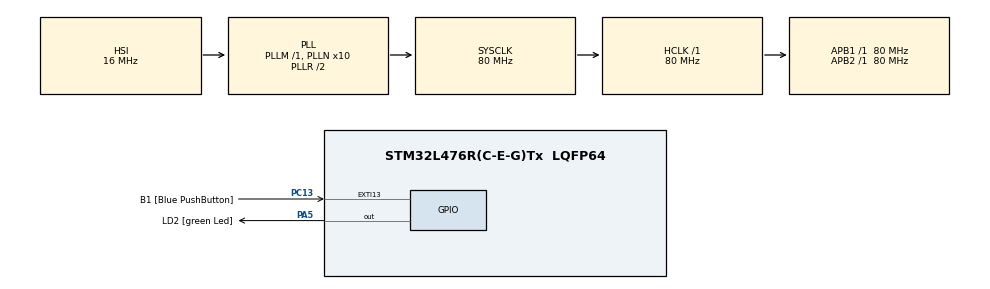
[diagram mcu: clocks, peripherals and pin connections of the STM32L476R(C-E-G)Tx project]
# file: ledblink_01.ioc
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Mcu.Family=STM32L4
Mcu.Name=STM32L476R(C-E-G)Tx
Mcu.Package=LQFP64
NVIC.PriorityGroup=NVIC_PRIORITYGROUP_4
NVIC.TIM3_IRQn=true\:0\:0\:false\:false\:true\:true
PA5.GPIO_Label=LD2 [green Led]
PA5.GPIO_ModeDefaultOutputPP=GPIO_MODE_OUTPUT_PP
PA5.GPIO_PuPd=GPIO_NOPULL
PA5.GPIO_Speed=GPIO_SPEED_FREQ_LOW
PA5.Signal=GPIO_Output
PC13.GPIO_Label=B1 [Blue PushButton]
PC13.GPIO_ModeDefaultEXTI=GPIO_MODE_IT_FALLING
PC13.GPIO_PuPd=GPIO_NOPULL
PC13.Signal=GPXTI13
PC14-OSC32_IN\ (PC14).Mode=LSE-External-Oscillator
PC14-OSC32_IN\ (PC14).Signal=RCC_OSC32_IN
PC15-OSC32_OUT\ (PC15).Mode=LSE-External-Oscillator
PC15-OSC32_OUT\ (PC15).Signal=RCC_OSC32_OUT
PH0-OSC_IN\ (PH0).Signal=RCC_OSC_IN
PH1-OSC_OUT\ (PH1).Signal=RCC_OSC_OUT
ProjectManager.HeapSize=0x200
ProjectManager.StackSize=0x400
ProjectManager.TargetToolchain=MDK-ARM V5
RCC.ADCFreq_Value=64000000
RCC.AHBFreq_Value=80000000
RCC.APB1Freq_Value=80000000
RCC.APB1TimFreq_Value=80000000
RCC.APB2Freq_Value=80000000
RCC.APB2TimFreq_Value=80000000
RCC.CortexFreq_Value=80000000
RCC.HCLKFreq_Value=80000000
RCC.HSE_VALUE=8000000
RCC.HSI_VALUE=16000000
RCC.MSI_VALUE=4000000
RCC.PLLN=10
RCC.PLLSourceVirtual=RCC_PLLSOURCE_HSI
RCC.PREFETCH_ENABLE=1
RCC.SYSCLKFreq_VALUE=80000000
RCC.SYSCLKSource=RCC_SYSCLKSOURCE_PLLCLK
RCC.USBFreq_Value=64000000
RCC.VCOOutputFreq_Value=160000000
TIM3.Prescaler=7999
VP_TIM3_VS_ClockSourceINT.Mode=Internal
board=NUCLEO-L476RG

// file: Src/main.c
/**
  ******************************************************************************
  * @file           : main.c
  * @brief          : Main program body
  ******************************************************************************
  ** This notice applies to any and all portions of this file
  * that are not between comment pairs USER CODE BEGIN and
  * USER CODE END. Other portions of this file, whether
  * inserted by the user or by software development tools
  * are owned by their respective copyright owners.
  *
  * COPYRIGHT(c) 2019 STMicroelectronics
  *
  * Redistribution and use in source and binary forms, with or without modification,
  * are permitted provided that the following conditions are met:
  *   1. Redistributions of source code must retain the above copyright notice,
  *      this list of conditions and the following disclaimer.
  *   2. Redistributions in binary form must reproduce the above copyright notice,
  *      this list of conditions and the following disclaimer in the documentation
  *      and/or other materials provided with the distribution.
  *   3. Neither the name of STMicroelectronics nor the names of its contributors
  *      may be used to endorse or promote products derived from this software
  *      without specific prior written permission.
  *
  * THIS SOFTWARE IS PROVIDED BY THE COPYRIGHT HOLDERS AND CONTRIBUTORS "AS IS"
  * AND ANY EXPRESS OR IMPLIED WARRANTIES, INCLUDING, BUT NOT LIMITED TO, THE
  * IMPLIED WARRANTIES OF MERCHANTABILITY AND FITNESS FOR A PARTICULAR PURPOSE ARE
  * DISCLAIMED. IN NO EVENT SHALL THE COPYRIGHT HOLDER OR CONTRIBUTORS BE LIABLE
  * FOR ANY DIRECT, INDIRECT, INCIDENTAL, SPECIAL, EXEMPLARY, OR CONSEQUENTIAL
  * DAMAGES (INCLUDING, BUT NOT LIMITED TO, PROCUREMENT OF SUBSTITUTE GOODS OR
  * SERVICES; LOSS OF USE, DATA, OR PROFITS; OR BUSINESS INTERRUPTION) HOWEVER
  * CAUSED AND ON ANY THEORY OF LIABILITY, WHETHER IN CONTRACT, STRICT LIABILITY,
  * OR TORT (INCLUDING NEGLIGENCE OR OTHERWISE) ARISING IN ANY WAY OUT OF THE USE
  * OF THIS SOFTWARE, EVEN IF ADVISED OF THE POSSIBILITY OF SUCH DAMAGE.
  *
  ******************************************************************************
  */
#include "main.h"
#include "stm32l4xx_hal.h"

TIM_HandleTypeDef htim3;

/* USER CODE BEGIN PV */
/* Private variables ---------------------------------------------------------*/

/* USER CODE END PV */

void SystemClock_Config(void);
static void MX_GPIO_Init(void);
static void MX_TIM3_Init(void);

/* USER CODE BEGIN PFP */
/* Private function prototypes -----------------------------------------------*/

/* USER CODE END PFP */

int main(void)
{

  /* MCU Configuration----------------------------------------------------------*/

  /* Reset of all peripherals, Initializes the Flash interface and the Systick. */
  HAL_Init();

  /* USER CODE BEGIN Init */
	int counter = 0;
  /* USER CODE END Init */

  /* Configure the system clock */
  SystemClock_Config();

  /* Initialize all configured peripherals */
  MX_GPIO_Init();
  MX_TIM3_Init();
  /* USER CODE BEGIN 2 */
	/* A Timert(3-ast) alap(base, nem pwm, nem encoder stb..) módban elindítjuk, úgy, hogy ha eléri a kívánt értéket,
	 * akkor interruptot generál. */
  HAL_TIM_Base_Start_IT(&htim3);
  /* USER CODE END 2 */

  /* Infinite loop */
  /* USER CODE BEGIN WHILE */
	/* A while(1) törzsében futó kód periódikusan meghívódik. Futását csak a külso interruptok szakítják meg.
	 * A kód célja, hogy gombnyomásra a led villogás frekvenciája megváltozzon, ehhez a led villogását idozíto
	 * Timer periódusidejét átállítjuk és a Timert újraindítjuk.
	*/
  while (1)
  {

  /* USER CODE END WHILE */
	/* Beolvassuk a nyomógombot, ami a PC13-as pin-en van. Ha lenyomjuk a nyomógombot,
	 * akkor LOW (0) logikai szint lesz a PC13-on.
	 * Alapvetoen gombokat nem így kezelünk, hanem célszeru IT-ként konfigurálni oket,
	 * ezzel elkerühetjük a folyamatos polling overheadet (hogy mindig ránézünk az értékére).
	 * Továbbá a jelen esetben használt HAL_Delay() fv. használata is inkább csak fejlesztés közben használatos,
	 * hiszen ekkor a uC várakozik. Az IT-os gomb "olvasással" erre nincs szükség, itt pergésmentesítés miatt volt használva.
	 * A counterek azért számlálnak 2-vel, mert a benne lévo kódot csak 1-szer szeretnénk, hogy lefusson
	 * (vsz. erre is gyorsan található szebb megoldás). */
	if ( HAL_GPIO_ReadPin(GPIOC, GPIO_PIN_13) == 0)
	{
		counter++;
		HAL_Delay(100);
	}

	if ( counter == 0)
	{
		htim3.Init.Period = 10000;
		HAL_TIM_Base_Init(&htim3);
		HAL_TIM_Base_Start_IT(&htim3);
		counter++;
	}

  if ( counter == 2)
	{
		htim3.Init.Period = 1000;
		HAL_TIM_Base_Init(&htim3);
		HAL_TIM_Base_Start_IT(&htim3);
		counter++;
	}

	if ( counter == 4)
	{
		htim3.Init.Period = 30000;
		HAL_TIM_Base_Init(&htim3);
		HAL_TIM_Base_Start_IT(&htim3);
		counter++;
	}

	if ( counter == 6)
	{
		counter = 0;
	}

  }

}

void SystemClock_Config(void)
{

  RCC_OscInitTypeDef RCC_OscInitStruct;
  RCC_ClkInitTypeDef RCC_ClkInitStruct;

    /**Initializes the CPU, AHB and APB busses clocks
    */
  RCC_OscInitStruct.OscillatorType = RCC_OSCILLATORTYPE_HSI;
  RCC_OscInitStruct.HSIState = RCC_HSI_ON;
  RCC_OscInitStruct.HSICalibrationValue = 16;
  RCC_OscInitStruct.PLL.PLLState = RCC_PLL_ON;
  RCC_OscInitStruct.PLL.PLLSource = RCC_PLLSOURCE_HSI;
  RCC_OscInitStruct.PLL.PLLM = 1;
  RCC_OscInitStruct.PLL.PLLN = 10;
  RCC_OscInitStruct.PLL.PLLP = RCC_PLLP_DIV7;
  RCC_OscInitStruct.PLL.PLLQ = RCC_PLLQ_DIV2;
  RCC_OscInitStruct.PLL.PLLR = RCC_PLLR_DIV2;
  if (HAL_RCC_OscConfig(&RCC_OscInitStruct) != HAL_OK)
  {
    _Error_Handler(__FILE__, __LINE__);
  }

    /**Initializes the CPU, AHB and APB busses clocks
    */
  RCC_ClkInitStruct.ClockType = RCC_CLOCKTYPE_HCLK|RCC_CLOCKTYPE_SYSCLK
                              |RCC_CLOCKTYPE_PCLK1|RCC_CLOCKTYPE_PCLK2;
  RCC_ClkInitStruct.SYSCLKSource = RCC_SYSCLKSOURCE_PLLCLK;
  RCC_ClkInitStruct.AHBCLKDivider = RCC_SYSCLK_DIV1;
  RCC_ClkInitStruct.APB1CLKDivider = RCC_HCLK_DIV1;
  RCC_ClkInitStruct.APB2CLKDivider = RCC_HCLK_DIV1;

  if (HAL_RCC_ClockConfig(&RCC_ClkInitStruct, FLASH_LATENCY_4) != HAL_OK)
  {
    _Error_Handler(__FILE__, __LINE__);
  }

    /**Configure the main internal regulator output voltage
    */
  if (HAL_PWREx_ControlVoltageScaling(PWR_REGULATOR_VOLTAGE_SCALE1) != HAL_OK)
  {
    _Error_Handler(__FILE__, __LINE__);
  }

    /**Configure the Systick interrupt time
    */
  HAL_SYSTICK_Config(HAL_RCC_GetHCLKFreq()/1000);

    /**Configure the Systick
    */
  HAL_SYSTICK_CLKSourceConfig(SYSTICK_CLKSOURCE_HCLK);

  /* SysTick_IRQn interrupt configuration */
  HAL_NVIC_SetPriority(SysTick_IRQn, 0, 0);
}

/* TIM3 init function */
static void MX_TIM3_Init(void)
{

  TIM_ClockConfigTypeDef sClockSourceConfig;
  TIM_MasterConfigTypeDef sMasterConfig;

  htim3.Instance = TIM3;
  htim3.Init.Prescaler = 7999;
  htim3.Init.CounterMode = TIM_COUNTERMODE_UP;
  htim3.Init.Period = 50000;
  htim3.Init.ClockDivision = TIM_CLOCKDIVISION_DIV1;
  htim3.Init.AutoReloadPreload = TIM_AUTORELOAD_PRELOAD_DISABLE;
//	htim3.Init.RepetitionCounter = 10000;
  if (HAL_TIM_Base_Init(&htim3) != HAL_OK)
  {
    _Error_Handler(__FILE__, __LINE__);
  }

  sClockSourceConfig.ClockSource = TIM_CLOCKSOURCE_INTERNAL;
  if (HAL_TIM_ConfigClockSource(&htim3, &sClockSourceConfig) != HAL_OK)
  {
    _Error_Handler(__FILE__, __LINE__);
  }

  sMasterConfig.MasterOutputTrigger = TIM_TRGO_RESET;
  sMasterConfig.MasterSlaveMode = TIM_MASTERSLAVEMODE_DISABLE;
  if (HAL_TIMEx_MasterConfigSynchronization(&htim3, &sMasterConfig) != HAL_OK)
  {
    _Error_Handler(__FILE__, __LINE__);
  }

}

/** Configure pins as
        * Analog
        * Input
        * Output
        * EVENT_OUT
        * EXTI
*/
static void MX_GPIO_Init(void)
{

  GPIO_InitTypeDef GPIO_InitStruct;

  /* GPIO Ports Clock Enable */
  __HAL_RCC_GPIOC_CLK_ENABLE();
  __HAL_RCC_GPIOH_CLK_ENABLE();
  __HAL_RCC_GPIOA_CLK_ENABLE();

  /*Configure GPIO pin Output Level */
  HAL_GPIO_WritePin(LD2_GPIO_Port, LD2_Pin, GPIO_PIN_RESET);

  /*Configure GPIO pin : B1_Pin */
  GPIO_InitStruct.Pin = B1_Pin;
  GPIO_InitStruct.Mode = GPIO_MODE_IT_FALLING;
  GPIO_InitStruct.Pull = GPIO_NOPULL;
  HAL_GPIO_Init(B1_GPIO_Port, &GPIO_InitStruct);

  /*Configure GPIO pin : LD2_Pin */
  GPIO_InitStruct.Pin = LD2_Pin;
  GPIO_InitStruct.Mode = GPIO_MODE_OUTPUT_PP;
  GPIO_InitStruct.Pull = GPIO_NOPULL;
  GPIO_InitStruct.Speed = GPIO_SPEED_FREQ_LOW;
  HAL_GPIO_Init(LD2_GPIO_Port, &GPIO_InitStruct);

}

void _Error_Handler(char *file, int line)
{
  while(1)
  {
  }
}

/************************ (C) COPYRIGHT STMicroelectronics *****END OF FILE****/
